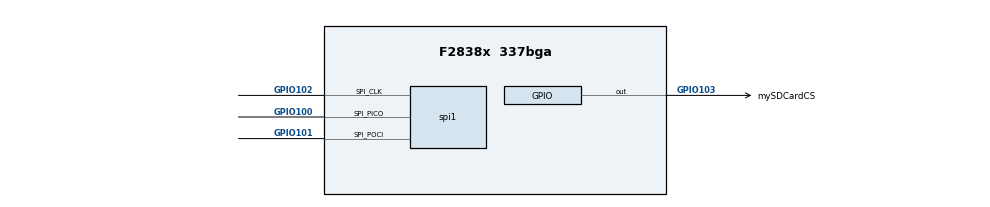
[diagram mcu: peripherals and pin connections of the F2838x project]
/**
 * @cliArgs --device "F2838x" --package "337bga" --part "F2838x_337bga" --product "C2000WARE@3.01.00.00"
 * @versions {"tool":"1.10.0+2163"}
 */

/**
 * Import the modules used in this configuration.
 */
const gpio  = scripting.addModule("/driverlib/gpio.js", {}, false);
const gpio1 = gpio.addInstance();
const spi   = scripting.addModule("/driverlib/spi.js", {}, false);
const spi1  = spi.addInstance();

/**
 * Write custom configuration values to the imported modules.
 */
gpio1.$name             = "mySDCardCS";
gpio1.writeInitialValue = true;
gpio1.initialValue      = 1;
gpio1.direction         = "GPIO_DIR_MODE_OUT";
gpio1.gpioPin.$assign   = "GPIO103";

spi1.mode                    = "SPI_MODE_MASTER";
spi1.emulationMode           = "SPI_EMULATION_STOP_AFTER_TRANSMIT";
spi1.bitRate                 = 1000000;
spi1.dataWidth               = "8";
spi1.transferProtocol        = "SPI_PROT_POL0PHA1";
spi1.$name                   = "mySDCardSPI";
spi1.useCase                 = "CUSTOM";
spi1.useInterfacePins        = ["SPI@_CLK","SPI@_PICO","SPI@_POCI"];
spi1.useInterrupts           = false;
spi1.spi.$assign             = "SPIC";
spi1.spi.spi_picoPin.$assign = "GPIO100";
spi1.spi.spi_pociPin.$assign = "GPIO101";
spi1.spi.spi_clkPin.$assign  = "GPIO102";
